AUTOSAR XML (schema 4-2-2)
package /System
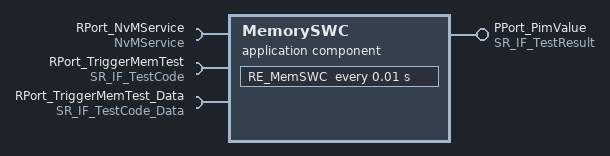
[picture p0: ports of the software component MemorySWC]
  application sw component type MemorySWC
    require port RPort_NvMService: required-interface=NvMService
    provide port PPort_PimValue: provided-interface=SR_IF_TestResult
    require port RPort_TriggerMemTest: required-interface=SR_IF_TestCode
    require port RPort_TriggerMemTest_Data: required-interface=SR_IF_TestCode_Data
    behavior SwcInternalBehavior_0: data-type-mapping=DataTypeMappingSet_ASW
      timing event TE_MemSW: start-on-event=RE_MemSWC, period=0.01
      per instance memory PIM_0: base-type=uint16, type=uint16, type-definition=uint16
      runnable RE_MemSWC
        data-receive-point-by-arguments:
          access DRA_TestCode_0: accessed-variable=RPort_TriggerMemTest.TestCode
          access DRA_TestCode_Data: accessed-variable=RPort_TriggerMemTest_Data.TestCode_Data
        data-send-points:
          access DWA_TestResult_0: accessed-variable=PPort_PimValue.TestResult
        9 x sync call:
          SynchronousServerCallPoint_0: operation=RPort_NvMService.EraseBlock
          SynchronousServerCallPoint_1: operation=RPort_NvMService.GetDataIndex
          SynchronousServerCallPoint_2: operation=RPort_NvMService.GetErrorStatus
          SynchronousServerCallPoint_3: operation=RPort_NvMService.InvalidateNvBlock
          SynchronousServerCallPoint_4: operation=RPort_NvMService.ReadBlock
          SynchronousServerCallPoint_5: operation=RPort_NvMService.RestoreBlockDefaults
          SynchronousServerCallPoint_6: operation=RPort_NvMService.SetDataIndex
          SynchronousServerCallPoint_7: operation=RPort_NvMService.SetRamBlockStatus
          SynchronousServerCallPoint_8: operation=RPort_NvMService.WriteBlock
      swc service dependency Srv_NvM_0: assigned-datas=role-based-data-assignment={role=ramBlock, used-pim=PIM_0}
        service-needs:
          nv block needs NvM_Needs_0: restore-at-start=true, store-at-shutdown=true
